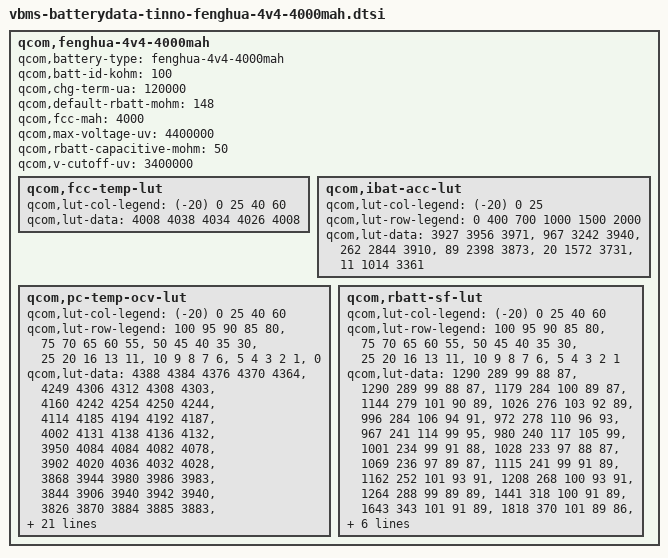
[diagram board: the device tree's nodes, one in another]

qcom,fenghua-4v4-4000mah {
	qcom,battery-type = "fenghua-4v4-4000mah";
	qcom,batt-id-kohm = <100>;
	qcom,chg-term-ua = <120000>;
	qcom,default-rbatt-mohm = <148>;
	qcom,fcc-mah = <4000>;
	qcom,max-voltage-uv = <4400000>;
	qcom,rbatt-capacitive-mohm = <50>;
	qcom,v-cutoff-uv = <3400000>;

	qcom,fcc-temp-lut {
		qcom,lut-col-legend = <(-20) 0 25 40 60>;
		qcom,lut-data = <4008 4038 4034 4026 4008>;
	};

	qcom,ibat-acc-lut {
		qcom,lut-col-legend = <(-20) 0 25>;
		qcom,lut-row-legend = <0 400 700 1000 1500 2000>;
		qcom,lut-data = <3927 3956 3971>,
				<967 3242 3940>,
				<262 2844 3910>,
				<89 2398 3873>,
				<20 1572 3731>,
				<11 1014 3361>;
	};

	qcom,pc-temp-ocv-lut {
		qcom,lut-col-legend = <(-20) 0 25 40 60>;
		qcom,lut-row-legend = <100 95 90 85 80>,
					<75 70 65 60 55>,
					<50 45 40 35 30>,
					<25 20 16 13 11>,
					<10 9 8 7 6>,
					<5 4 3 2 1>,
					<0>;
		qcom,lut-data = <4388 4384 4376 4370 4364>,
				<4249 4306 4312 4308 4303>,
				<4160 4242 4254 4250 4244>,
				<4114 4185 4194 4192 4187>,
				<4002 4131 4138 4136 4132>,
				<3950 4084 4084 4082 4078>,
				<3902 4020 4036 4032 4028>,
				<3868 3944 3980 3986 3983>,
				<3844 3906 3940 3942 3940>,
				<3826 3870 3884 3885 3883>,
				<3810 3839 3851 3851 3850>,
				<3794 3814 3826 3826 3824>,
				<3780 3796 3805 3805 3804>,
				<3764 3783 3788 3788 3786>,
				<3750 3772 3772 3770 3766>,
				<3734 3759 3756 3748 3736>,
				<3717 3740 3737 3728 3715>,
				<3700 3720 3716 3708 3694>,
				<3684 3706 3697 3688 3676>,
				<3672 3696 3689 3681 3670>,
				<3664 3693 3687 3680 3669>,
				<3654 3689 3686 3678 3667>,
				<3642 3684 3684 3677 3666>,
				<3627 3676 3681 3674 3662>,
				<3608 3663 3674 3666 3652>,
				<3584 3637 3650 3641 3621>,
				<3549 3593 3605 3596 3574>,
				<3500 3529 3545 3536 3513>,
				<3426 3434 3464 3454 3430>,
				<3290 3279 3338 3330 3302>,
				<3011 3000 3052 3000 3000>;
	};

	qcom,rbatt-sf-lut {
		qcom,lut-col-legend = <(-20) 0 25 40 60>;
		qcom,lut-row-legend = <100 95 90 85 80>,
					<75 70 65 60 55>,
					<50 45 40 35 30>,
					<25 20 16 13 11>,
					<10 9 8 7 6>,
					<5 4 3 2 1>;
		qcom,lut-data = <1290 289 99 88 87>,
				<1290 289 99 88 87>,
				<1179 284 100 89 87>,
				<1144 279 101 90 89>,
				<1026 276 103 92 89>,
				<996 284 106 94 91>,
				<972 278 110 96 93>,
				<967 241 114 99 95>,
				<980 240 117 105 99>,
				<1001 234 99 91 88>,
				<1028 233 97 88 87>,
				<1069 236 97 89 87>,
				<1115 241 99 91 89>,
				<1162 252 101 93 91>,
				<1208 268 100 93 91>,
				<1264 288 99 89 89>,
				<1441 318 100 91 89>,
				<1643 343 101 91 89>,
				<1818 370 101 89 86>,
				<1903 377 100 89 88>,
				<1836 387 101 91 89>,
				<1972 403 103 92 92>,
				<2147 422 106 95 96>,
				<2375 445 109 99 99>,
				<2653 464 112 100 99>,
				<2970 482 108 95 91>,
				<3428 507 106 92 91>,
				<4120 557 109 95 92>,
				<5288 641 116 97 95>,
				<9816 1281 135 113 111>;
	};
};
/* TEST_DB_ID=TEST_ID_NOT_SET */
